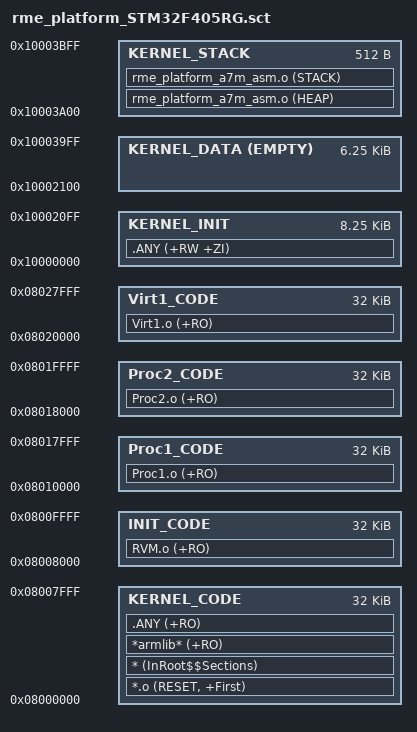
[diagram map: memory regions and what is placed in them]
;******************************************************************************
;Filename    : rme_platform_STM32F405RG.sct
;Author      : The RME project generator.
;Date        : 08/10/2019
;Licence     : LGPL v3+; see COPYING for details.
;Description : The scatter file for ARMv7-M layout. This file is intended
;              to be used with STM32F405RG.
;******************************************************************************

; Begin Segment:KERNEL ********************************************************
; Description : The kernel segment, this is where the kernel of the operating
;               system is located at. This segment also contains the .bss(ZI)
;               for processes.
; *****************************************************************************
KERNEL 0x8000000 0x8000
{
    ; Kernel code segment
    KERNEL_CODE 0x8000000 0x8000
    {
        ; The reset vectors
        *.o                            (RESET, +First)
        ; The lib code copying code
        *                              (InRoot$$Sections)
        ; The ARM C library code - all of them is here
        *armlib*                       (+RO)
        ; The kernel code section
        .ANY                           (+RO)
    }

    ; Kernel stack segment
    KERNEL_STACK 0x10003A00 0x200
    {
        rme_platform_a7m_asm.o             (HEAP)
        rme_platform_a7m_asm.o             (STACK)
    }

    ; Initial kernel data segment
    KERNEL_INIT 0x10000000 0x2100
    {
        .ANY                           (+RW +ZI)
    }

    ; Dynamically managed kernel data segment
    KERNEL_DATA 0x10002100 EMPTY 0x1900
    {

    }
}
; End Segment:KERNEL **********************************************************

; Begin Segment:INIT **********************************************************
; Description : The .text segment of process INIT. Init is the first process
;               in the system, and should act as a memory manager itself.
; *****************************************************************************
INIT 0x8008000 0x8000
{
    ; Init process code segment
    INIT_CODE 0x8008000 0x8000
    {
        RVM.o                          (+RO)
    }
}
; End Segment:INIT ************************************************************

; Begin Segment:Proc **********************************************************
; Description : The .text segment of the virtual machines. All virtual machines
; needs to be placed here; If you don't want to convert them to C and compile to
; a whole image, flash them to this address.
; *****************************************************************************
Proc1 0x8010000 0x8000
{
    ; Init process code segment
    Proc1_CODE 0x8010000 0x8000
    {
        Proc1.o                         (+RO)
    }
}
; End Segment:VM **************************************************************

; Begin Segment:Proc **********************************************************
; Description : The .text segment of the virtual machines. All virtual machines
; needs to be placed here; If you don't want to convert them to C and compile to
; a whole image, flash them to this address.
; *****************************************************************************
Proc2 0x8018000 0x8000
{
    ; Init process code segment
    Proc2_CODE 0x8018000 0x8000
    {
        Proc2.o                         (+RO)
    }
}
; End Segment:VM **************************************************************

; Begin Segment:Proc **********************************************************
; Description : The .text segment of the virtual machines. All virtual machines
; needs to be placed here; If you don't want to convert them to C and compile to
; a whole image, flash them to this address.
; *****************************************************************************
Virt1 0x8020000 0x8000
{
    ; Init process code segment
    Virt1_CODE 0x8020000 0x8000
    {
        Virt1.o                         (+RO)
    }
}
; End Segment:VM **************************************************************

; End Of File *****************************************************************

; Copyright (C) Evo-Devo Instrum. All rights reserved *************************


